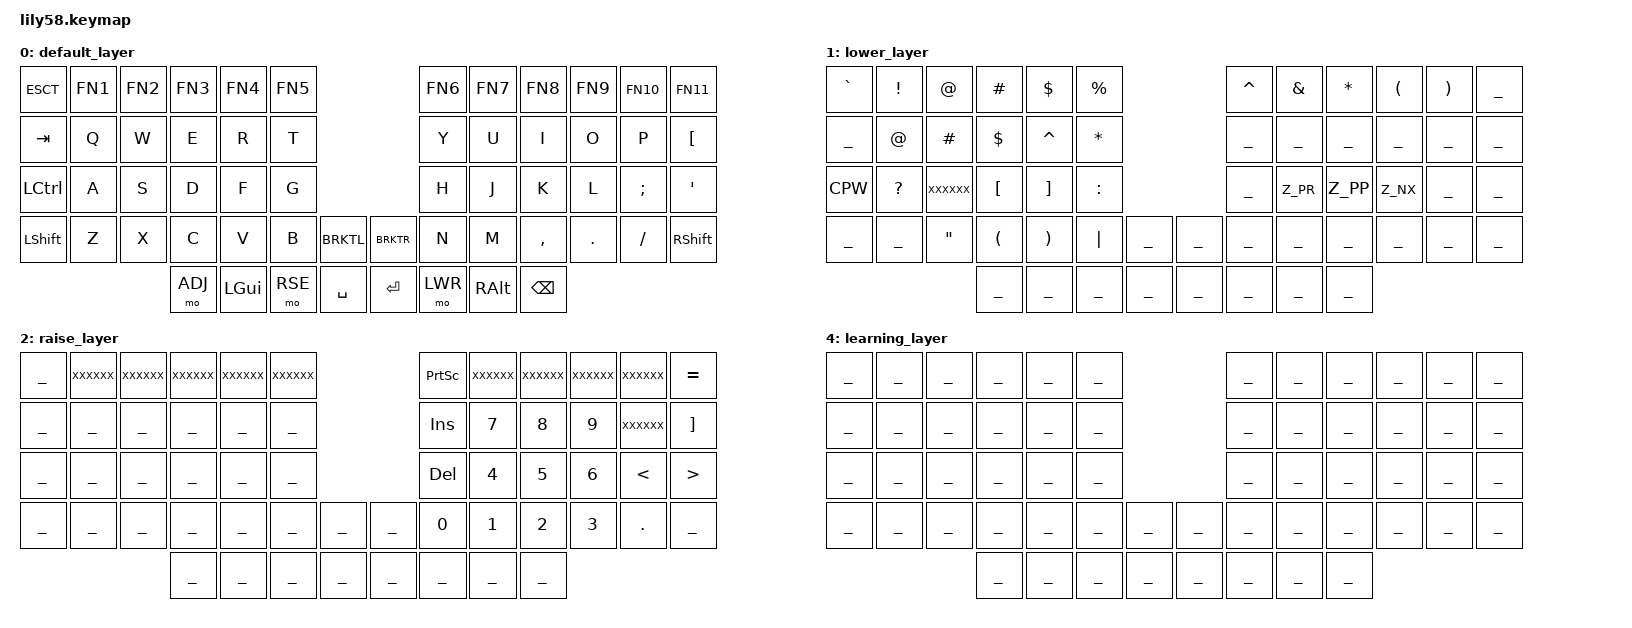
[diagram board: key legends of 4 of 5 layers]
/*
 * Copyright (c) 2020 The ZMK Contributors
 *
 * SPDX-License-Identifier: MIT
 */

#include <behaviors.dtsi>
#include <dt-bindings/zmk/keys.h>
#include <dt-bindings/zmk/bt.h>
#include <dt-bindings/zmk/outputs.h>
#include "lily58.h"

&mt {
    flavor = "tap-preferred";
    tapping-term-ms = <400>;
    quick-tap-ms = <200>;
};

&caps_word {
    continue-list = <UNDER MINUS BSPC>;
};

/ {
     behaviors {
        soft_off_plus: soft_off_plus {
            compatible = "zmk,behavior-soft-off-plus";
            #binding-cells = <0>;
            hold-time-ms = <1200>;
        };
    };
    
    keymap {
                compatible = "zmk,keymap";

                default_layer {
                      bindings = <
    
//                ┌────────┬────────┬────────┬────────┬────────┬────────┐                      ┌────────┬────────┬────────┬────────┬────────┬────────┐
                     ESCT     FN1      FN2      FN3      FN4      FN5                              FN6     FN7      FN8      FN9      FN10     FN11
//                ├────────┼────────┼────────┼────────┼────────┼────────┤                      ├────────┼────────┼────────┼────────┼────────┼────────┤
                   &kp TAB   &kp Q    &kp W    &kp E    &kp R    &kp T                            &kp Y   &kp U    &kp I    &kp O    &kp P   &kp LBKT
//                ├────────┼────────┼────────┼────────┼────────┼────────┤                      ├────────┼────────┼────────┼────────┼────────┼────────┤
                  &kp LCTRL  &kp A    &kp S    &kp D    &kp F    &kp G                            &kp H   &kp J    &kp K    &kp L   &kp SEMI &kp SQT
//                ├────────┼────────┼────────┼────────┼────────┼────────┼────────┐    ┌────────┼────────┼────────┼────────┼────────┼────────┼────────┤
                  &kp LSHFT  &kp Z    &kp X    &kp C    &kp V    &kp B     BRKTL        BRKTR    &kp N   &kp M  &kp COMMA &kp DOT &kp SLASH &kp RSHFT
//                └────────┴────────┴─────┬──┴─────┬──┴─────┬──┴─────┬──┴────────┤    ├────────┴──┬─────┴──┬─────┴──┬─────┴──┬─────┴────────┴────────┘
                                           &mo ADJ  &kp LGUI  &mo RSE  &kp SPACE        &kp ENTER  &mo LWR  &kp RALT &kp BKSP
//                                        └────────┴────────┴────────┴───────────┘    └───────────┴────────┴────────┴────────┘
                       >;
                };

                lower_layer {
                      bindings = <

//                ┌────────┬────────┬────────┬────────┬────────┬────────┐                      ┌────────┬────────┬────────┬────────┬────────┬────────┐
                  &kp GRAVE &kp EXCL  &kp AT  &kp HASH &kp DLLR &kp PRCNT                      &kp CARET &kp AMPS &kp STAR &kp LPRN &kp RPRN &kp UNDER  
//                ├────────┼────────┼────────┼────────┼────────┼────────┤                      ├────────┼────────┼────────┼────────┼────────┼────────┤
                    ______   &kp AT  &kp HASH &kp DLLR &kp CARET &kp STAR                        ______   ______   ______   ______   ______   ______
//                ├────────┼────────┼────────┼────────┼────────┼────────┤                      ├────────┼────────┼────────┼────────┼────────┼────────┤
                     CPW   &kp QMARK  XXXXXX  &kp LBKT &kp RBKT &kp COLN                         ______    Z_PR     Z_PP     Z_NX    ______   ______
//                ├────────┼────────┼────────┼────────┼────────┼────────┼────────┐    ┌────────┼────────┼────────┼────────┼────────┼────────┼────────┤
                    ______ &kp UNDER &kp DQT  &kp LPRN &kp RPRN &kp PIPE  ______        ______   ______   ______   ______   ______   ______   ______
//                └────────┴────────┴─────┬──┴─────┬──┴─────┬──┴─────┬──┴────────┤    ├────────┴──┬─────┴──┬─────┴──┬─────┴──┬─────┴────────┴────────┘
                                            ______   ______   ______      ______        ______      ______   ______   ______
//                                        └────────┴────────┴────────┴───────────┘    └───────────┴────────┴────────┴────────┘
                       >;
                };

                raise_layer {
                     bindings = <

//                ┌────────┬────────┬────────┬────────┬────────┬────────┐                      ┌────────┬────────┬────────┬────────┬────────┬────────┐
                    ______   XXXXXX   XXXXXX   XXXXXX   XXXXXX   XXXXXX                        &kp PSCRN  XXXXXX   XXXXXX   XXXXXX   XXXXXX   &kp EQL
//                ├────────┼────────┼────────┼────────┼────────┼────────┤                      ├────────┼────────┼────────┼────────┼────────┼────────┤
                    ______   ______   ______   ______   ______   ______                         &kp INS   &kp N7   &kp N8   &kp N9   XXXXXX  &kp RBKT
//                ├────────┼────────┼────────┼────────┼────────┼────────┤                      ├────────┼────────┼────────┼────────┼────────┼────────┤
                    ______   ______   ______   ______   ______   ______                          &kp DEL  &kp N4   &kp N5   &kp N6   &kp LT   &kp GT
//                ├────────┼────────┼────────┼────────┼────────┼────────┼────────┐    ┌────────┼────────┼────────┼────────┼────────┼────────┼────────┤
                    ______   ______   ______   ______   ______   ______   ______        ______   &kp N0   &kp N1   &kp N2   &kp N3   &kp DOT  ______
//                └────────┴────────┴─────┬──┴─────┬──┴─────┬──┴─────┬──┴────────┤    ├────────┴──┬─────┴──┬─────┴──┬─────┴──┬─────┴────────┴────────┘
                                            ______   ______   ______      ______        ______      ______   ______   ______
//                                        └────────┴────────┴────────┴───────────┘    └───────────┴────────┴────────┴────────┘
                      >;
                };

                adjust_layer {
                     bindings = <

//                ┌──[0]───┬──[1]───┬──[2]───┬──[3]───┬──[4]───┬──[5]───┐                      ┌──[6]───┬──[7]───┬──[8]───┬──[9]───┬──[10]──┬──[11]──┐
                    ______   Z_BT_0   Z_BT_1   Z_BT_2   Z_BT_3   Z_BT_4                          Z_VUP    XXXXXX   XXXXXX   XXXXXX   XXXXXX   XXXXXX
//                ├──[12]──┼──[13]──┼──[14]──┼──[15]──┼──[16]──┼──[17]──┤                      ├──[18]──┼──[19]──┼──[20]──┼──[21]──┼──[22]──┼──[23]──┤
                    ______   ______   ______   ______   OUT_T    Z_BT_C                          Z_VDN   &kp HOME  &kp UP  &kp END  &kp PGUP &kp BSLH
//                ├──[24]──┼──[25]──┼──[26]──┼──[27]──┼──[28]──┼──[29]──┤                      ├──[30]──┼──[31]──┼──[32]──┼──[33]──┼──[34]──┼──[35]──┤
                    ______   ______   ______   ______   ______   ______                          Z_MUT   &kp LEFT &kp DOWN &kp RIGHT &kp PGDN ______
//                ├──[36]──┼──[37]──┼──[38]──┼──[39]──┼──[40]──┼──[41]──┼──[52]──┐    ┌──[53]──┼──[42]──┼──[43]──┼──[44]──┼──[45]──┼──[46]──┼──[47]──┤
                    ______   ______   ______   ______    Z_OFF   Z_BOOT   &vim_s        &vim_q   Z_BOOT    Z_OFF   ______   ______  &kp BSLH  ______
//                └────────┴────────┴─────┬──┴[48]─┬──┴[49]─┬──┴[50]─┬──┴──[51]──┤    ├──[54]──┴──┬─[55]┴──┬─[56]┴──┬─[57]┴──┬─────┴────────┴────────┘
                                            ______   ______   ______    ______            ______    ______   ______   ______
//                                        └────────┴────────┴────────┴───────────┘    └───────────┴────────┴────────┴────────┘
                      >;
                };

                learning_layer {
                     bindings = <

//                ┌──[0]───┬──[1]───┬──[2]───┬──[3]───┬──[4]───┬──[5]───┐                      ┌──[6]───┬──[7]───┬──[8]───┬──[9]───┬──[10]──┬──[11]──┐
                    ______   ______   ______   ______   ______   ______                          ______   ______   ______   ______   ______   ______ 
//                ├──[12]──┼──[13]──┼──[14]──┼──[15]──┼──[16]──┼──[17]──┤                      ├──[18]──┼──[19]──┼──[20]──┼──[21]──┼──[22]──┼──[23]──┤
                    ______   ______   ______   ______   ______   ______                          ______   ______   ______  ______    ______   ______ 
//                ├──[24]──┼──[25]──┼──[26]──┼──[27]──┼──[28]──┼──[29]──┤                      ├──[30]──┼──[31]──┼──[32]──┼──[33]──┼──[34]──┼──[35]──┤
                    ______   ______   ______   ______   ______   ______                          ______   ______   ______  ______    ______   ______
//                ├──[36]──┼──[37]──┼──[38]──┼──[39]──┼──[40]──┼──[41]──┼──[52]──┐    ┌──[53]──┼──[42]──┼──[43]──┼──[44]──┼──[45]──┼──[46]──┼──[47]──┤
                    ______   ______   ______   ______    ______  ______   ______        ______   ______    ______  ______   ______   ______   ______
//                └────────┴────────┴─────┬──┴[48]─┬──┴[49]─┬──┴[50]─┬──┴──[51]──┤    ├──[54]──┴──┬─[55]┴──┬─[56]┴──┬─[57]┴──┬─────┴────────┴────────┘
                                            ______   ______   ______    ______          ______      ______   ______   ______
//                                        └────────┴────────┴────────┴───────────┘    └───────────┴────────┴────────┴────────┘
                      >;
                };
        };

    combos {
        compatible = "zmk,combos";
        COMBO(learnl, &tog LRN, 29 30)
        COMBO(caps,   &kp CAPS, 25 34)
    };
    
    macros {
        MACRO(vim_q,  &kp COLON &kp Q &kp EXCL)
        MACRO(vim_s,  &kp COLON &kp W &kp Q)
        MACRO(dir_up, &kp DOT &kp DOT &kp FSLH)
    };
};
